# HT32F52342_52 register map
File version: 1.0
CPU: CM0+ r0p1, little endian, no MPU, no FPU, 4 interrupt priority bits
Registers are 32-bit, read-write, reset 0x0 unless marked. A register's access mark holds for its fields unless they carry their own. Offsets are from the block's base; [hi:lo] are bit positions; {n}, {i} and the like mark numbered series.

## GPTM0
Base 0x4006E000
Same registers: GPTM1 0x4006F000
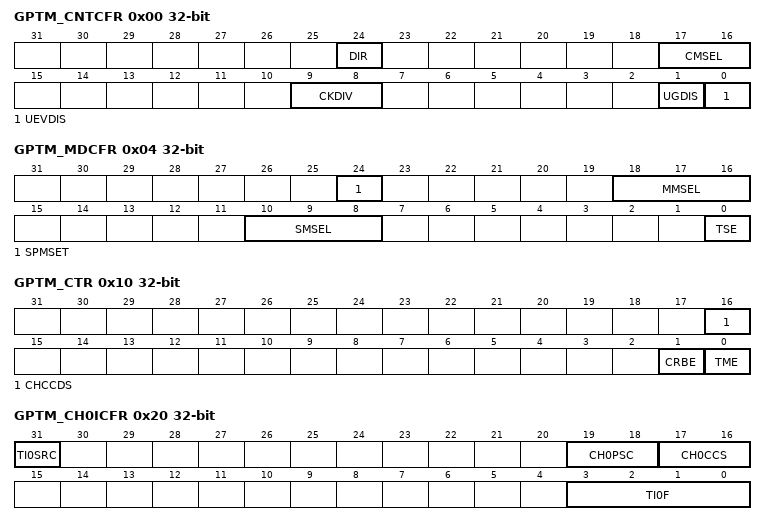
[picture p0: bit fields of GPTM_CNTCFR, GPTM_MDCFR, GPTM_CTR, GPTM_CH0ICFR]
0x00 GPTM_CNTCFR
  [24] DIR, [17:16] CMSEL, [9:8] CKDIV, [1] UGDIS, [0] UEVDIS
0x04 GPTM_MDCFR
  [24] SPMSET, [18:16] MMSEL, [10:8] SMSEL, [0] TSE
0x08 GPTM_TRCFR
  [3:0] TRSEL
0x10 GPTM_CTR
  [16] CHCCDS, [1] CRBE, [0] TME
0x20 GPTM_CH0ICFR
  [31] TI0SRC, [19:18] CH0PSC, [17:16] CH0CCS, [3:0] TI0F
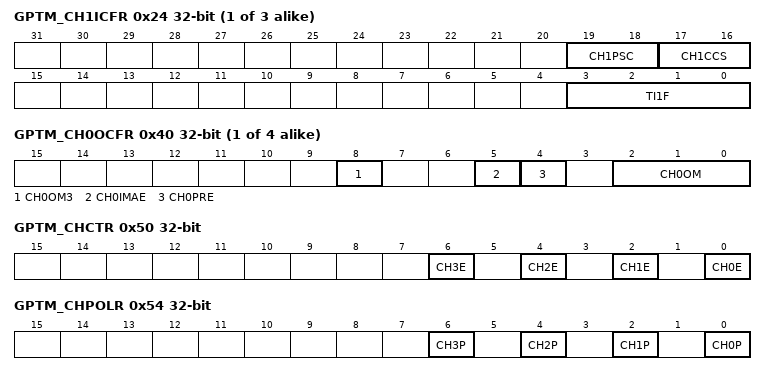
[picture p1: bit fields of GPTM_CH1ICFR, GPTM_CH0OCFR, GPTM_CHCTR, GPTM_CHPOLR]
{0x20+4i} GPTM_CH{i}ICFR (i=1..3)
  [19:18] CH{i}PSC, [17:16] CH{i}CCS, [3:0] TI{i}F
{0x40+4i} GPTM_CH{i}OCFR (i=0..3)
  [8] CH{i}OM3, [5] CH{i}IMAE, [4] CH{i}PRE, [2:0] CH{i}OM
0x50 GPTM_CHCTR
  [2n] CH{n}E (n=0..3)
0x54 GPTM_CHPOLR
  [2n] CH{n}P (n=0..3)
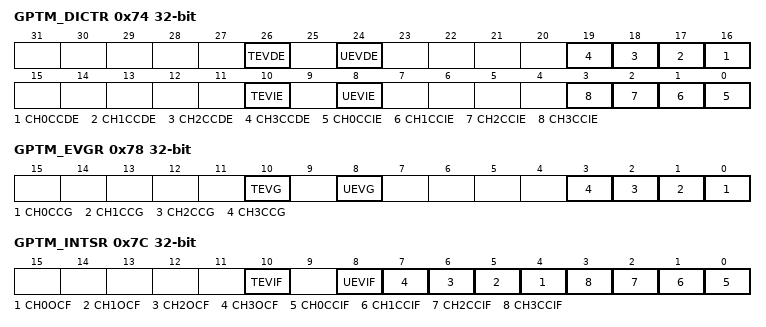
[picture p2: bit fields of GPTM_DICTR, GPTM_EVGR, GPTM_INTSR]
0x74 GPTM_DICTR
  [26] TEVDE, [24] UEVDE, [n+16] CH{n}CCDE (n=0..3), [10] TEVIE, [8] UEVIE, [n] CH{n}CCIE (n=0..3)
0x78 GPTM_EVGR
  [10] TEVG, [8] UEVG, [n] CH{n}CCG (n=0..3)
0x7C GPTM_INTSR
  [10] TEVIF, [8] UEVIF, [n+4] CH{n}OCF (n=0..3), [n] CH{n}CCIF (n=0..3)
0x80 GPTM_CNTR
  [15:0] CNTV
0x84 GPTM_PSCR
  [15:0] PSCV
0x88 GPTM_CRR
  [15:0] CRV
{0x90+4i} GPTM_CH{i}CCR (i=0..3)
  [15:0] CH{i}CCV
{0xA0+4i} GPTM_CH{i}ACR (i=0..3)
  [15:0] CH{i}ACV

## SCTM0
Base 0x40034000
Same registers: SCTM1 0x40074000
Registers as GPTM0, without GPTM_CNTCFR, GPTM_CH{n}ICFR (n=1..3), GPTM_CH0OCFR, GPTM_CH2OCFR, GPTM_CH3OCFR, GPTM_CH{n}CCR (n=1..3), GPTM_CH{n}ACR (n=0..3); these are added or differ:
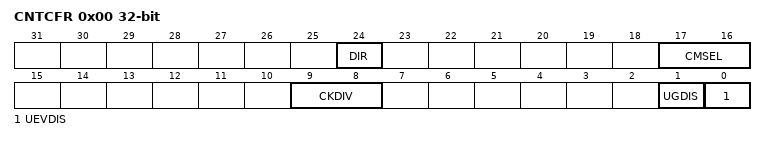
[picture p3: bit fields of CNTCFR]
0x00 CNTCFR
  [24] DIR, [17:16] CMSEL, [9:8] CKDIV, [1] UGDIS, [0] UEVDIS

## BFTM0
Base 0x40076000
Same registers: BFTM1 0x40077000
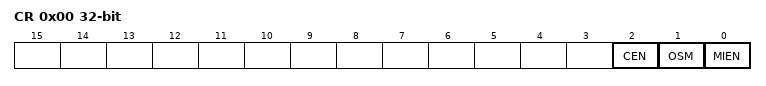
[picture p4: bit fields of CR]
0x00 CR
  [2] CEN, [1] OSM, [0] MIEN
0x04 SR
  [0] MIF
0x08 CNTR
0x0C CMPR
  [31:0] CMP

## RTC
Base 0x4006A000
0x00 CNT
  [31:0] RTCCNT
0x04 CMP
  [31:0] RTCCMP
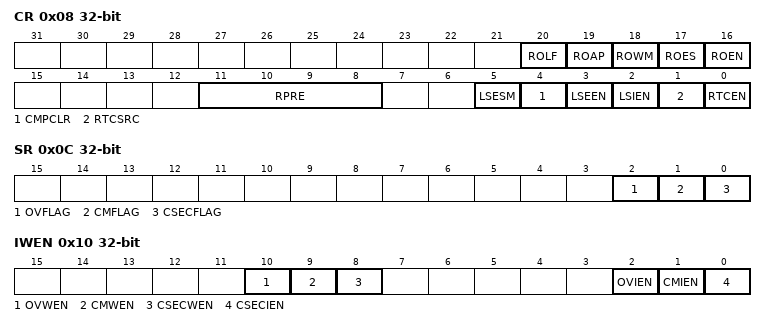
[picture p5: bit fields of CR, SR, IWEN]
0x08 CR
  [20] ROLF, [19] ROAP, [18] ROWM, [17] ROES, [16] ROEN, [11:8] RPRE, [5] LSESM, [4] CMPCLR, [3] LSEEN, [2] LSIEN, [1] RTCSRC, [0] RTCEN
0x0C SR
  [2] OVFLAG, [1] CMFLAG, [0] CSECFLAG
0x10 IWEN
  [10] OVWEN, [9] CMWEN, [8] CSECWEN, [2] OVIEN, [1] CMIEN, [0] CSECIEN

## WDT
Base 0x40068000
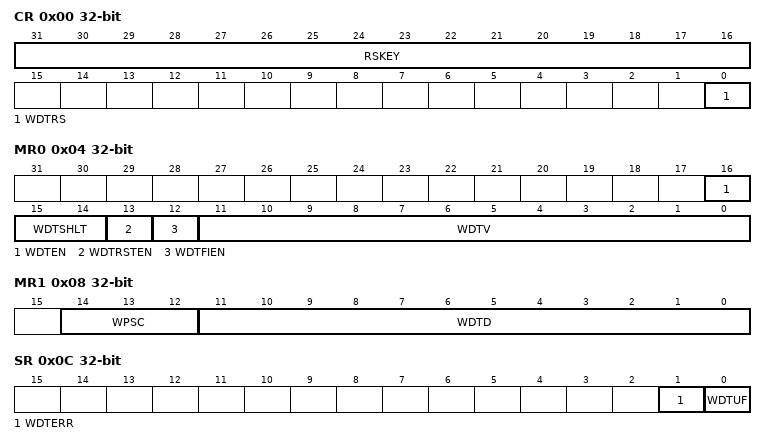
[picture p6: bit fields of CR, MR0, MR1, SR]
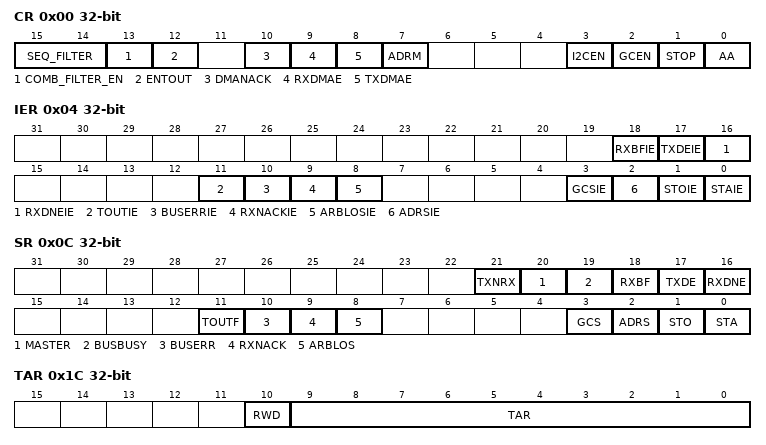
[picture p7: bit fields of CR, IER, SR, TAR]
0x00 CR
  [31:16] RSKEY, [0] WDTRS
0x04 MR0
  [16] WDTEN, [15:14] WDTSHLT, [13] WDTRSTEN, [12] WDTFIEN, [11:0] WDTV
0x08 MR1
  [14:12] WPSC, [11:0] WDTD
0x0C SR
  [1] WDTERR, [0] WDTUF
0x10 PR
  [15:0] PROTECT

## I2C0
Base 0x40048000
Same registers: I2C1 0x40049000
0x00 CR
  [15:14] SEQ_FILTER, [13] COMB_FILTER_EN, [12] ENTOUT, [10] DMANACK, [9] RXDMAE, [8] TXDMAE, [7] ADRM, [3] I2CEN, [2] GCEN, [1] STOP, [0] AA
0x04 IER
  [18] RXBFIE, [17] TXDEIE, [16] RXDNEIE, [11] TOUTIE, [10] BUSERRIE, [9] RXNACKIE, [8] ARBLOSIE, [3] GCSIE, [2] ADRSIE, [1] STOIE, [0] STAIE
0x08 ADDR
  [9:0] ADDR
0x0C SR
  [21] TXNRX, [20] MASTER, [19] BUSBUSY, [18] RXBF, [17] TXDE, [16] RXDNE, [11] TOUTF, [10] BUSERR, [9] RXNACK, [8] ARBLOS, [3] GCS, [2] ADRS, [1] STO, [0] STA
0x10 SHPGR
  [15:0] SHPG
0x14 SLPGR
  [15:0] SLPG
0x18 DR
  [7:0] DATA
0x1C TAR
  [10] RWD, [9:0] TAR
0x20 ADDMR
  [9:0] ADDMR
0x24 ADDSR
  [9:0] ADDSR
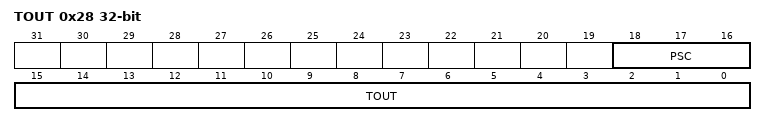
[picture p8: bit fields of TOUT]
0x28 TOUT
  [18:16] PSC, [15:0] TOUT

## SPI0
Base 0x40004000
Same registers: SPI1 0x40044000
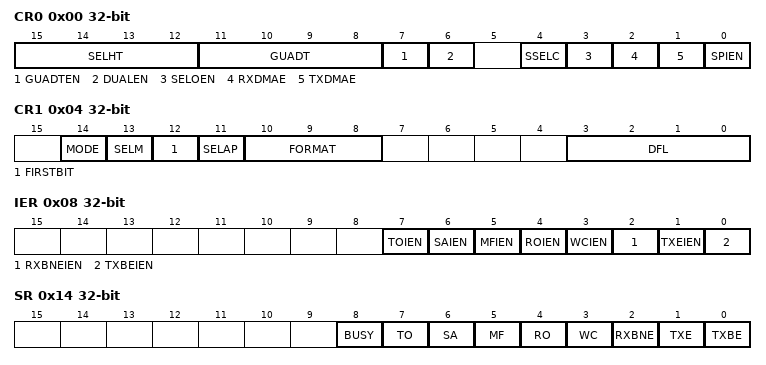
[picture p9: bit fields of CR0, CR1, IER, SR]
0x00 CR0
  [15:12] SELHT, [11:8] GUADT, [7] GUADTEN, [6] DUALEN, [4] SSELC, [3] SELOEN, [2] RXDMAE, [1] TXDMAE, [0] SPIEN
0x04 CR1
  [14] MODE, [13] SELM, [12] FIRSTBIT, [11] SELAP, [10:8] FORMAT, [3:0] DFL
0x08 IER
  [7] TOIEN, [6] SAIEN, [5] MFIEN, [4] ROIEN, [3] WCIEN, [2] RXBNEIEN, [1] TXEIEN, [0] TXBEIEN
0x0C CPR
  [15:0] CP
0x10 DR
  [15:0] DR
0x14 SR
  [8] BUSY, [7] TO, [6] SA, [5] MF, [4] RO, [3] WC, [2] RXBNE, [1] TXE, [0] TXBE
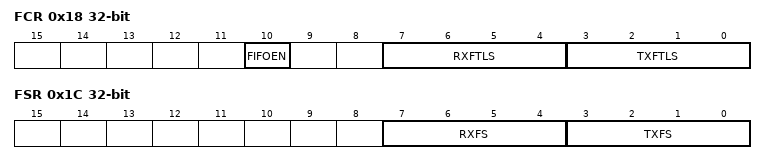
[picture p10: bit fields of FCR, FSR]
0x18 FCR
  [10] FIFOEN, [7:4] RXFTLS, [3:0] TXFTLS
0x1C FSR
  [7:4] RXFS, [3:0] TXFS
0x20 FTOCR
  [15:0] TOC

## USART0
Base 0x40000000
Same registers: USART1 0x40040000
0x00 USART_USRDR
  [8:0] DB
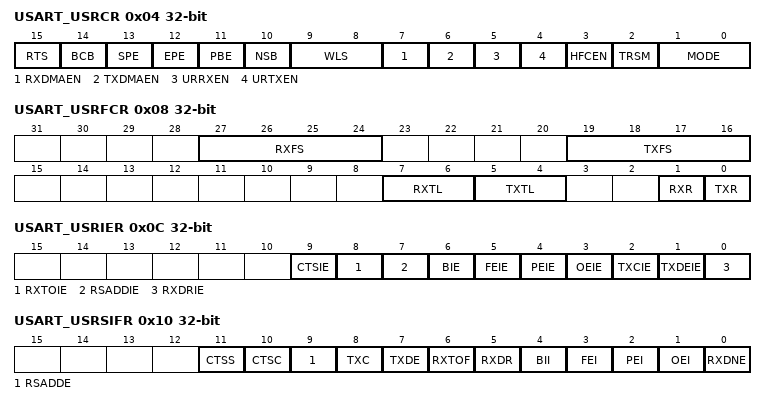
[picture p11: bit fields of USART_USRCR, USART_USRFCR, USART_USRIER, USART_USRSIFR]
0x04 USART_USRCR
  [15] RTS, [14] BCB, [13] SPE, [12] EPE, [11] PBE, [10] NSB, [9:8] WLS, [7] RXDMAEN, [6] TXDMAEN, [5] URRXEN, [4] URTXEN, [3] HFCEN, [2] TRSM, [1:0] MODE
0x08 USART_USRFCR
  [27:24] RXFS, [19:16] TXFS, [7:6] RXTL, [5:4] TXTL, [1] RXR, [0] TXR
0x0C USART_USRIER
  [9] CTSIE, [8] RXTOIE, [7] RSADDIE, [6] BIE, [5] FEIE, [4] PEIE, [3] OEIE, [2] TXCIE, [1] TXDEIE, [0] RXDRIE
0x10 USART_USRSIFR
  [11] CTSS, [10] CTSC, [9] RSADDE, [8] TXC, [7] TXDE, [6] RXTOF, [5] RXDR, [4] BII, [3] FEI, [2] PEI, [1] OEI, [0] RXDNE
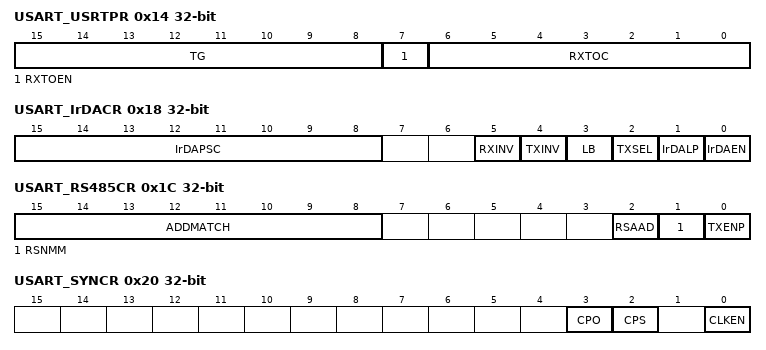
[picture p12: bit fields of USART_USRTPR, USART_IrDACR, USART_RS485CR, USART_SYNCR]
0x14 USART_USRTPR
  [15:8] TG, [7] RXTOEN, [6:0] RXTOC
0x18 USART_IrDACR
  [15:8] IrDAPSC, [5] RXINV, [4] TXINV, [3] LB, [2] TXSEL, [1] IrDALP, [0] IrDAEN
0x1C USART_RS485CR
  [15:8] ADDMATCH, [2] RSAAD, [1] RSNMM, [0] TXENP
0x20 USART_SYNCR
  [3] CPO, [2] CPS, [0] CLKEN
0x24 USART_USRDLR
  [15:0] BRD
0x28 USART_USRTSTR
  [1:0] LBM
